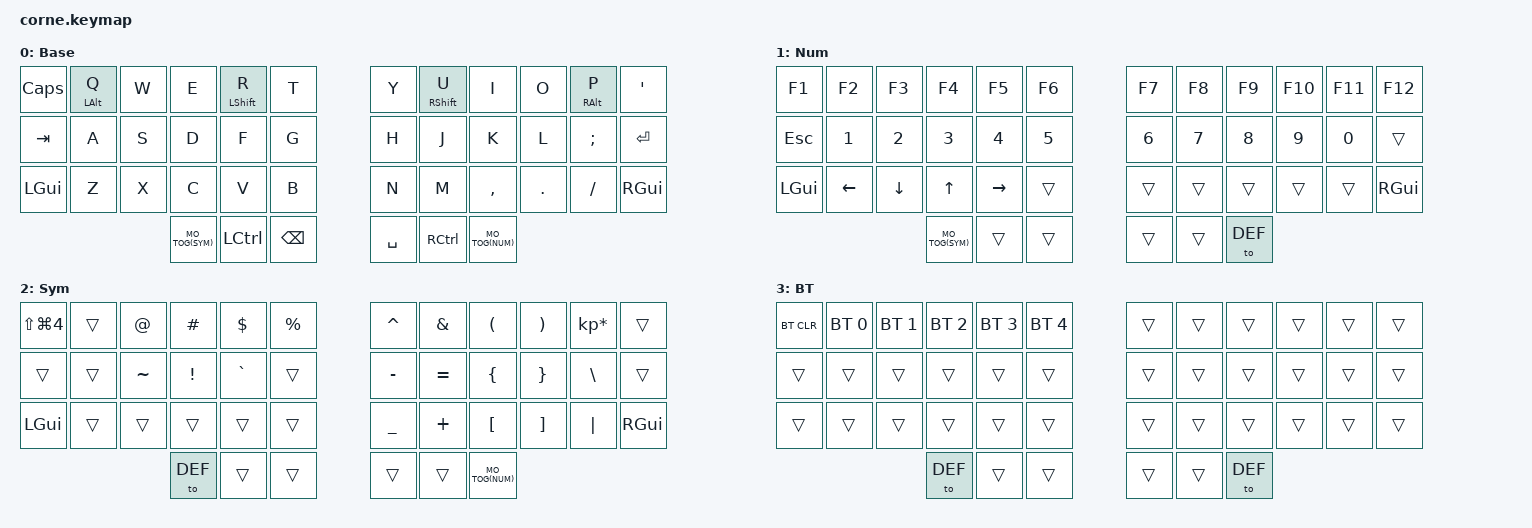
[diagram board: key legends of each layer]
/*
 * Copyright (c) 2020 The ZMK Contributors
 *
 * SPDX-License-Identifier: MIT
 */

#include <behaviors.dtsi>
#include <dt-bindings/zmk/keys.h>
#include <dt-bindings/zmk/bt.h>

#define DEF 0
#define NUM 1
#define SYM 2
#define BT 3

#define MO_TOG(layer) &mo_tog layer layer

/ {
    behaviors {
        bhm: balanced_homerow_mods {
            compatible = "zmk,behavior-hold-tap";
            #binding-cells = <2>;
            tapping-term-ms = <200>;    // <---[[moderate duration]]
            quick-tap-ms = <0>;
            flavor = "balanced";
            bindings = <&kp>, <&kp>;
        };
	mo_tog: behavior_mo_tog {
            compatible = "zmk,behavior-hold-tap";
            #binding-cells = <2>;
            flavor = "hold-preferred";
            tapping-term-ms = <200>;
            bindings = <&mo>, <&tog>;
        };
	rpi: require_prior_idle {
  	    compatible = "zmk,behavior-hold-tap";
            #binding-cells = <2>;
            flavor = "tap-preferred";
            tapping-term-ms = <200>;
            quick-tap-ms = <200>;
            require-prior-idle-ms = <125>;
            bindings = <&kp>, <&kp>;
        };
	td_caps: tap_dance_caps_lock {
            compatible = "zmk,behavior-tap-dance";
            #binding-cells = <0>;
            tapping-term-ms = <200>;
            bindings = <&kp CAPS>, <&kp ESC>;
        };
    };
    combos {
        compatible = "zmk,combos";
	combo_bt {
	    timeout-ms = <50>;
	    key-positions = <0 11>;
	    bindings = <&to BT>;
	};
    };
    
        keymap {
                compatible = "zmk,keymap";

                default_layer {
// -----------------------------------------------------------------------------------------
// |  CAPS |  Q  |  W  |  E  |  R   |  T   |   |  Y  |  U    |  I  |  O  |  P  | '"  |
// |  TAB  |  A  |  S  |  D  |  F   |  G   |   |  H  |  J    |  K  |  L  | ;:  | RET |
// |  GUI  |  Z  |  X  |  C  |  V   |  B   |   |  N  |  M    | ,<  | .>  | /?  | GUI |
//                     | SYM | CTRL | BKSP |   | SPC | CTRL  | NUM |
                        display-name = "Base";
                        bindings = <
   &kp CAPS &rpi LALT Q  &kp W &kp E       &rpi LSHIFT R &kp T     &kp Y     &rpi RSHIFT U  &kp I     &kp O   &rpi RALT P &kp SQT
   &kp TAB  &kp A        &kp S &kp D       &kp F         &kp G     &kp H     &kp J          &kp K     &kp L   &kp SEMI    &kp RET
   &kp LGUI &kp Z        &kp X &kp C       &kp V         &kp B     &kp N     &kp M          &kp COMMA &kp DOT &kp FSLH    &kp RGUI
                               MO_TOG(SYM) &kp LCTRL     &kp BKSP  &kp SPACE &kp RCTRL      MO_TOG(NUM)
                        >;
                };
                num_layer {
// -----------------------------------------------------------------------------------------
// | F1   | F2  | F3  | F4  | F5  | F6  |   | F7  | F8  | F9  | F10 | F11 | F12 |
// | ESC  |  1  |  2  |  3  |  4  |  5  |   |  6  |  7  |  8  |  9  |  0  |     |
// | GUI  | LFT | DWN | UP  | RGT |     |   |     |     |     |     |     | GUI |
//                    | SYM |     |     |   |     |     | DEF |
                        display-name = "Num";
                        bindings = <
   &kp F1   &kp F2   &kp F3   &kp F4      &kp F5    &kp F6   &kp F7 &kp F8 &kp F9 &kp F10 &kp F11 &kp F12
   &kp ESC  &kp N1   &kp N2   &kp N3      &kp N4    &kp N5   &kp N6 &kp N7 &kp N8 &kp N9  &kp N0  &trans
   &kp LGUI &kp LEFT &kp DOWN &kp UP      &kp RIGHT &trans   &trans &trans &trans &trans  &trans  &kp RGUI
                              MO_TOG(SYM) &trans    &trans   &trans &trans &to DEF
                        >;
                };
                sym_layer {
// -----------------------------------------------------------------------------------------
// | SCRN |     |  @  |  #  |  $  |  %  |   |  ^  |  &  |  (  |  )  |  *  |     |
// |      |     |  ~  |  !  |  `  |     |   |  -  |  =  |  {  |  }  |  \  |     |
// | GUI  |     |     |     |     |     |   |  _  |  +  |  [  |  ]  | "|" | GUI |
//                    | DEF |     |     |   |     |     | NUM |
                        display-name = "Sym";
                        bindings = <
   &kp LS(LG(N4)) &trans &kp AT    &kp HASH &kp DLLR  &kp PRCNT &kp CARET &kp AMPS  &kp LPAR &kp RPAR &kp KP_MULTIPLY &trans
   &trans         &trans &kp TILDE &kp EXCL &kp GRAVE &trans    &kp MINUS &kp EQUAL &kp LBRC &kp RBRC &kp BSLH        &trans
   &kp LGUI       &trans &trans    &trans   &trans    &trans    &kp UNDER &kp PLUS  &kp LBKT &kp RBKT &kp PIPE        &kp RGUI
                                   &to DEF  &trans    &trans    &trans    &trans    MO_TOG(NUM)
                        >;
                };
                bt_layer {
// -----------------------------------------------------------------------------------------
// | BTCLR| BT0 | BT1 | BT2 | BT3 | BT4 |   |     |     |     |     |     |     |
// |      |     |     |     |     |     |   |     |     |     |     |     |     |
// |      |     |     |     |     |     |   |     |     |     |     |     |     |
//                    | DEF |     |     |   |     |     | DEF |
                        display-name = "BT";
                        bindings = <
   &bt BT_CLR &bt BT_SEL 0 &bt BT_SEL 1 &bt BT_SEL 2 &bt BT_SEL 3 &bt BT_SEL 4   &trans &trans &trans &trans &trans &trans
   &trans     &trans       &trans       &trans       &trans       &trans         &trans &trans &trans &trans &trans &trans
   &trans     &trans       &trans       &trans       &trans       &trans         &trans &trans &trans &trans &trans &trans
                          	        &to DEF      &trans       &trans         &trans &trans &to DEF
                        >;
                };
        };
};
